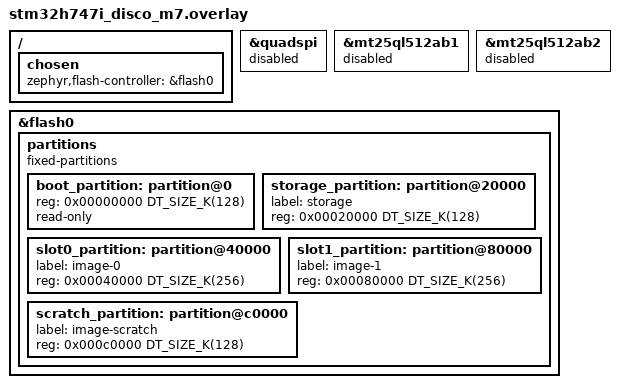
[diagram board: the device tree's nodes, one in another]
/*
 * Copyright (c) 2022 STMicroelectronics
 *
 * SPDX-License-Identifier: Apache-2.0
 */

/delete-node/ &storage_partition;

/ {
        chosen {
                zephyr,flash-controller = &flash0;
        };
};

&quadspi {
        status = "disabled";
};

&mt25ql512ab1 {
        status = "disabled";
};

&mt25ql512ab2 {
        status = "disabled";
};

&flash0 {
        status = "okay";
	partitions {
		compatible = "fixed-partitions";
		#address-cells = <1>;
		#size-cells = <1>;

		/* 128KB for bootloader */
		boot_partition: partition@0 {
			reg = <0x00000000 DT_SIZE_K(128)>;
			read-only;
		};

		/* storage: 128KB for settings */
		storage_partition: partition@20000 {
			label = "storage";
			reg = <0x00020000 DT_SIZE_K(128)>;
		};

		/* application image slot: 256KB */
		slot0_partition: partition@40000 {
			label = "image-0";
			reg = <0x00040000 DT_SIZE_K(256)>;
		};

		/* backup slot: 256KB */
		slot1_partition: partition@80000 {
			label = "image-1";
			reg = <0x00080000 DT_SIZE_K(256)>;
		};

		/* swap slot: 128KB */
		scratch_partition: partition@c0000 {
			label = "image-scratch";
			reg = <0x000c0000 DT_SIZE_K(128)>;
		};

	};
};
